VERSION ""

NS_ :

BS_:

BU_:

BO_ 3221225472 VECTOR__INDEPENDENT_SIG_MSG: 0 Vector__XXX
 SG_ NewSignal_0002 : 8|8@1+ (1,0) [0|0] "" Vector__XXX

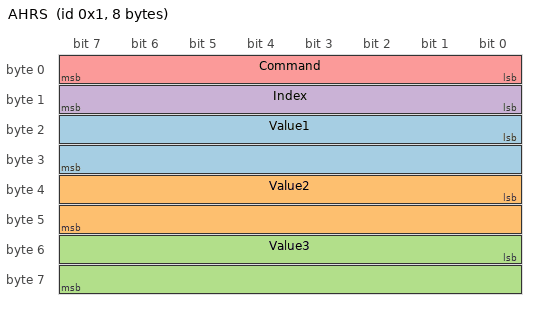
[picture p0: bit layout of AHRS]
BO_ 1 AHRS: 8 Vector__XXX
 SG_ Value1 : 16|16@1- (1,0) [0|0] "" Vector__XXX
 SG_ Value2 : 32|16@1- (1,0) [0|0] "" Vector__XXX
 SG_ Value3 : 48|16@1- (1,0) [0|0] "" Vector__XXX
 SG_ Index : 8|8@1+ (1,0) [51|54] "" Vector__XXX
 SG_ Command : 0|8@1- (1,0) [0|0] "" Vector__XXX

CM_ BO_ 1 "x_axis, y_axis, z_axis   [acceleration]        Value1,2,3/1000

x_axis, y_axis, z_axis   [angular velocity]   Value1,2,3/10 

Roll , Pitch, Yaw            [Euler angle]          Value1,2,3/100

x_axis, y_axis, z_axis   [magnetic field]       Value1,2,3/10";
CM_ SG_ 1 Index "51(0x33) acc data
52(0x34) gyo data
53(0x35) deg data
54(0x36) mag data";
CM_ SG_ 1 Command "(0xF0)";
